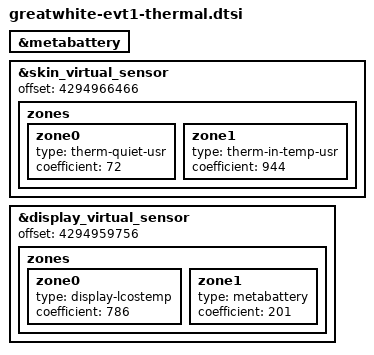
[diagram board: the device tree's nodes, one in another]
&metabattery {
	#thermal-sensor-cells = <0>;
};

&skin_virtual_sensor{
	// Equation is T = 0.072 * therm-quiet-usr + 0.944 * therm-in-temp-usr - 0.83
	// 32 bit 2's complement -830
	offset = <4294966466>;
	zones {
		zone0 {
			type = "therm-quiet-usr";
			coefficient = <72>;
		};
		zone1 {
			type = "therm-in-temp-usr";
			coefficient = <944>;
		};
	};
};

&display_virtual_sensor{
	// Equation is T = -7.540 + 0.786 * display-lcostemp + 0.201 * metabattery
	offset = <4294959756>;
	zones {
		zone0 {
		type = "display-lcostemp";
		coefficient = <786>;
		};
		zone1 {
		type = "metabattery";
		coefficient = <201>;
		};
	};
};
